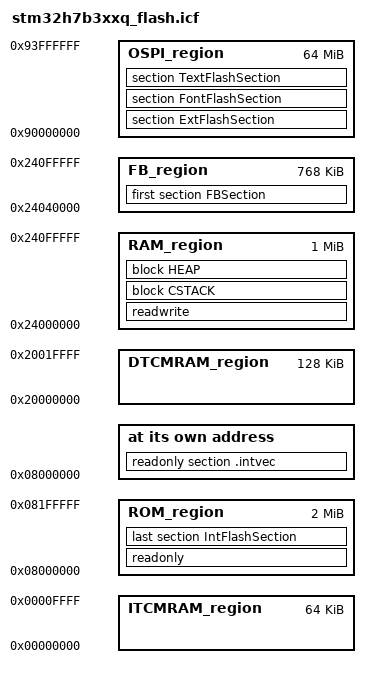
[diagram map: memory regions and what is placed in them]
/*###ICF### Section handled by ICF editor, don't touch! ****/
/*-Editor annotation file-*/
/* IcfEditorFile="$TOOLKIT_DIR$\config\ide\IcfEditor\cortex_v1_0.xml" */
/*-Specials-*/
define symbol __ICFEDIT_intvec_start__ = 0x08000000;
/*-Memory Regions-*/
define symbol __ICFEDIT_region_ROM_start__     = 0x08000000;
define symbol __ICFEDIT_region_ROM_end__       = 0x081FFFFF;
define symbol __ICFEDIT_region_ITCMRAM_start__ = 0x00000000;
define symbol __ICFEDIT_region_ITCMRAM_end__   = 0x0000FFFF; /*   64 Kbytes */
define symbol __ICFEDIT_region_DTCMRAM_start__ = 0x20000000;
define symbol __ICFEDIT_region_DTCMRAM_end__   = 0x2001FFFF; /*  128 Kbytes */
define symbol __ICFEDIT_region_RAM_start__     = 0x24000000;
define symbol __ICFEDIT_region_RAM_end__       = 0x240FFFFF; /* 1024 Kbytes */
define symbol __ICFEDIT_region_FBMEM_start__   = 0x24040000;
define symbol __ICFEDIT_region_FBMEM_end__     = 0x240FFFFF; /*  768 Kbytes */

/*-Quad-SPI Memory Regions-*/
define symbol __ICFEDIT_region_OSPI_start__    = 0x90000000;
define symbol __ICFEDIT_region_OSPI_end__      = 0x93FFFFFF; /*  64 Mbytes external flash */

/*-Sizes-*/
define symbol __ICFEDIT_size_cstack__ = 0x1000;
define symbol __ICFEDIT_size_heap__ = 0x1000;
/**** End of ICF editor section. ###ICF###*/

define memory mem with size = 4G;
define region ITCMRAM_region    = mem:[from __ICFEDIT_region_ITCMRAM_start__    to __ICFEDIT_region_ITCMRAM_end__];
define region DTCMRAM_region    = mem:[from __ICFEDIT_region_DTCMRAM_start__    to __ICFEDIT_region_DTCMRAM_end__];
define region ROM_region   = mem:[from __ICFEDIT_region_ROM_start__   to __ICFEDIT_region_ROM_end__];
define region RAM_region   = mem:[from __ICFEDIT_region_RAM_start__   to __ICFEDIT_region_RAM_end__];
define region FB_region    = mem:[from __ICFEDIT_region_FBMEM_start__ to __ICFEDIT_region_FBMEM_end__];
define region OSPI_region  = mem:[from __ICFEDIT_region_OSPI_start__  to __ICFEDIT_region_OSPI_end__];

define block CSTACK    with alignment = 8, size = __ICFEDIT_size_cstack__   { };
define block HEAP      with alignment = 8, size = __ICFEDIT_size_heap__     { };

initialize by copy { readwrite };
do not initialize  { section .noinit };

place at address mem:__ICFEDIT_intvec_start__ { readonly section .intvec };

place in ROM_region   { readonly, last section IntFlashSection };
place in RAM_region   { readwrite,
                        block CSTACK, block HEAP };
place in FB_region    { first section FBSection };
place in OSPI_region  { section ExtFlashSection, section FontFlashSection, section TextFlashSection };
